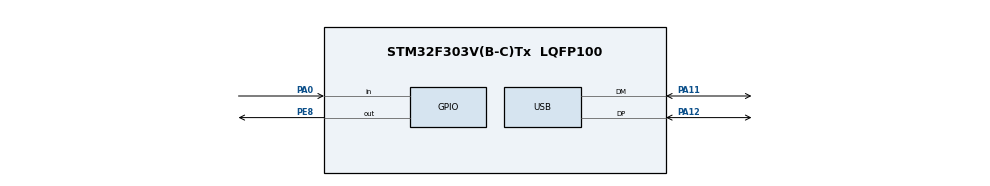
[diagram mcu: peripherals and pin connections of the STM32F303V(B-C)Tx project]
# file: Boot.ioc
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Mcu.Family=STM32F3
Mcu.Name=STM32F303V(B-C)Tx
Mcu.Package=LQFP100
NVIC.PriorityGroup=NVIC_PRIORITYGROUP_0
PA0.GPIO_PuPd=GPIO_PULLDOWN
PA0.Signal=GPIO_Input
PA11.Mode=Device
PA11.Signal=USB_DM
PA12.Mode=Device
PA12.Signal=USB_DP
PE8.Signal=GPIO_Output
PF0-OSC_IN.GPIO_Label=OSC_IN
PF0-OSC_IN.Mode=HSE-External-Clock-Source
PF0-OSC_IN.Signal=RCC_OSC_IN
ProjectManager.HeapSize=0x200
ProjectManager.StackSize=0x400
ProjectManager.TargetToolchain=STM32CubeIDE
RCC.AHBFreq_Value=72000000
RCC.APB1CLKDivider=RCC_HCLK_DIV2
RCC.APB1Freq_Value=36000000
RCC.APB1TimFreq_Value=72000000
RCC.APB2Freq_Value=72000000
RCC.APB2TimFreq_Value=72000000
RCC.CortexFreq_Value=72000000
RCC.HCLKFreq_Value=72000000
RCC.HSE_VALUE=8000000
RCC.HSI_VALUE=8000000
RCC.LSE_VALUE=32768
RCC.PLLMUL=RCC_PLL_MUL9
RCC.PLLSourceVirtual=RCC_PLLSOURCE_HSE
RCC.PRESCALERUSB=RCC_USBCLKSOURCE_PLL_DIV1_5
RCC.SYSCLKFreq_VALUE=72000000
RCC.SYSCLKSourceVirtual=RCC_SYSCLKSOURCE_PLLCLK
RCC.USBFreq_Value=48000000
board=STM32F3DISCOVERY

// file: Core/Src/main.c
/* USER CODE BEGIN Header */
/**
  ******************************************************************************
  * @file           : main.c
  * @brief          : Main program body
  ******************************************************************************
  * @attention
  *
  * <h2><center>&copy; Copyright (c) 2020 STMicroelectronics.
  * All rights reserved.</center></h2>
  *
  * This software component is licensed by ST under BSD 3-Clause license,
  * the "License"; You may not use this file except in compliance with the
  * License. You may obtain a copy of the License at:
  *                        opensource.org/licenses/BSD-3-Clause
  *
  ******************************************************************************
  */
/* USER CODE END Header */
#include "main.h"

/* USER CODE BEGIN Includes */
#include "app.h"
/* USER CODE END Includes */

PCD_HandleTypeDef hpcd_USB_FS;

void SystemClock_Config(void);
static void MX_GPIO_Init(void);
void MX_USB_PCD_Init(void);

int main(void)
{

  /* MCU Configuration--------------------------------------------------------*/

  /* Reset of all peripherals, Initializes the Flash interface and the Systick. */
  HAL_Init();

  /* Configure the system clock */
  SystemClock_Config();

  /* Initialize all configured peripherals */
  MX_GPIO_Init();
  /* USER CODE BEGIN 2 */
  /* Initialize the bootloader application. */
  AppInit();
  /* USER CODE END 2 */

  /* Infinite loop */
  /* USER CODE BEGIN WHILE */
  while (1)
  {
    /* Run the bootloader application. */
    AppTask();
    /* USER CODE END WHILE */

  }
}

void SystemClock_Config(void)
{
  LL_FLASH_SetLatency(LL_FLASH_LATENCY_2);
  while(LL_FLASH_GetLatency()!= LL_FLASH_LATENCY_2)
  {
  }
  LL_RCC_HSE_EnableBypass();
  LL_RCC_HSE_Enable();

   /* Wait till HSE is ready */
  while(LL_RCC_HSE_IsReady() != 1)
  {

  }
  LL_RCC_PLL_ConfigDomain_SYS(LL_RCC_PLLSOURCE_HSE_DIV_1, LL_RCC_PLL_MUL_9);
  LL_RCC_PLL_Enable();

   /* Wait till PLL is ready */
  while(LL_RCC_PLL_IsReady() != 1)
  {

  }
  LL_RCC_SetAHBPrescaler(LL_RCC_SYSCLK_DIV_1);
  LL_RCC_SetAPB1Prescaler(LL_RCC_APB1_DIV_2);
  LL_RCC_SetAPB2Prescaler(LL_RCC_APB1_DIV_1);
  LL_RCC_SetSysClkSource(LL_RCC_SYS_CLKSOURCE_PLL);

   /* Wait till System clock is ready */
  while(LL_RCC_GetSysClkSource() != LL_RCC_SYS_CLKSOURCE_STATUS_PLL)
  {

  }
  LL_SetSystemCoreClock(72000000);

   /* Update the time base */
  if (HAL_InitTick (TICK_INT_PRIORITY) != HAL_OK)
  {
    Error_Handler();
  }
  LL_RCC_SetUSBClockSource(LL_RCC_USB_CLKSOURCE_PLL_DIV_1_5);
}

void MX_USB_PCD_Init(void)
{

  /* USER CODE BEGIN USB_Init 0 */
  /* Note that this function is generated but not actually used. The bootloader handles
   * the USB initialization.
   */

  /* USER CODE END USB_Init 0 */

  hpcd_USB_FS.Instance = USB;
  hpcd_USB_FS.Init.dev_endpoints = 8;
  hpcd_USB_FS.Init.speed = PCD_SPEED_FULL;
  hpcd_USB_FS.Init.phy_itface = PCD_PHY_EMBEDDED;
  hpcd_USB_FS.Init.low_power_enable = DISABLE;
  hpcd_USB_FS.Init.battery_charging_enable = DISABLE;
  if (HAL_PCD_Init(&hpcd_USB_FS) != HAL_OK)
  {
    Error_Handler();
  }

}

static void MX_GPIO_Init(void)
{
  LL_GPIO_InitTypeDef GPIO_InitStruct = {0};

  /* GPIO Ports Clock Enable */
  LL_AHB1_GRP1_EnableClock(LL_AHB1_GRP1_PERIPH_GPIOF);
  LL_AHB1_GRP1_EnableClock(LL_AHB1_GRP1_PERIPH_GPIOA);
  LL_AHB1_GRP1_EnableClock(LL_AHB1_GRP1_PERIPH_GPIOE);

  /**/
  LL_GPIO_ResetOutputPin(GPIOE, LL_GPIO_PIN_8);

  /**/
  GPIO_InitStruct.Pin = LL_GPIO_PIN_0;
  GPIO_InitStruct.Mode = LL_GPIO_MODE_INPUT;
  GPIO_InitStruct.Pull = LL_GPIO_PULL_DOWN;
  LL_GPIO_Init(GPIOA, &GPIO_InitStruct);

  /**/
  GPIO_InitStruct.Pin = LL_GPIO_PIN_8;
  GPIO_InitStruct.Mode = LL_GPIO_MODE_OUTPUT;
  GPIO_InitStruct.Speed = LL_GPIO_SPEED_FREQ_LOW;
  GPIO_InitStruct.OutputType = LL_GPIO_OUTPUT_PUSHPULL;
  GPIO_InitStruct.Pull = LL_GPIO_PULL_NO;
  LL_GPIO_Init(GPIOE, &GPIO_InitStruct);

}

void Error_Handler(void)
{
}

/************************ (C) COPYRIGHT STMicroelectronics *****END OF FILE****/
